# FLASH register map
Vendor: Texas Instruments
Peripheral module from a debugger description file (folder CC27xxx7).
Registers are 32-bit, read-only, reset 0x0 unless marked. A register's access mark holds for its fields unless they carry their own. Offsets are as the file gives them; lines under a group give offsets from that group; [hi:lo] are bit positions; {n}, {i} and the like mark numbered series; 'fields as' and 'values as' point back to an identical list; <NAME> marks a mode.

## FLASH — This is the MMR space for the flash wrapper. The flash wrapper is targeting multiple microcontroller platforms. The flash wrapper is a module that manages complex flash read, program and erase memory operations. The system is also given direct access to read flash memory contents directly for each instantiated flash bank through FBAP ports.
0x28 IMASK access per field — Interrupt Mask Register: The IMASK register holds the current interrupt mask settings. Masked interrupts are read in the MIS register. PSD compliant register.
  [0] DONE rw — Interrupt mask for DONE: 0: Interrupt is disabled in MIS register 1: Interrupt is enabled in MIS register
    1=ENABLED (Interrupt will request an interrupt service routine and corresponding bit in IPSTANDARD.MIS will be set); 0=DISABLED (Interrupt is masked out)
0x30 RIS — Raw Interrupt Status Register: The RIS register reflects all pending interrupts, regardless of masking. The RIS register allows the user to implement a poll scheme. A flag set in this register can be cleared by writing a 1 to the ICLR register bit even if the corresponding IMASK bit is not enabled. A flag can be set by software by writing a 1 to the ISET register. Reading the IIDX register will also clear the corresponding bit in RIS. PSD compliant register.
  [0] DONE — Flash wrapper operation completed. This interrupt bit is set by firmware or the corresponding bit in the ISET register. It is cleared by the corresponding bit in in the ICLR register or reading the IIDX register when this interrupt is the highest priority.
    1=SET (Interrupt occurred); 0=CLR (Interrupt did not occur)
0x38 MIS — Masked Interrupt Status Register: The MIS register is a bit-wise AND of the contents of the IMASK and RIS registers. This is kept mainly for ARM compatibility, and has limited use since the highest priority interrupt index is returned through the IIDX register. PSD compliant register.
  [0] DONE — Flash wrapper operation completed. This masked interrupt bit reflects the bitwise AND of the corresponding RIS and IMASK bits.
    1=SET (Masked interrupt occurred); 0=CLR (Masked interrupt did not occur)
0x40 ISET wo — Interrupt Set Register: The ISET register allows software to write a 1 to set corresponding interrupt. Safety: This meets a safety requirement to allow software diagnostics to trigger interrupts. PSD compliant register.
  [0] DONE — 0: No effect 1: Set the DONE interrupt in the RIS register
    1=SET (Set IPSTANDARD.RIS bit); 0=NO_EFFECT (Writing a 0 has no effect)
0x48 ICLR wo — Interrupt Clear Register. The ICLR register allows allows software to write a 1 to clear corresponding interrupt. PSD compliant register.
  [0] DONE — 0: No effect 1: Clear the DONE interrupt in the RIS register
    1=CLR (Clear IPSTANDARD.RIS bit); 0=NO_EFFECT (Writing a 0 has no effect)
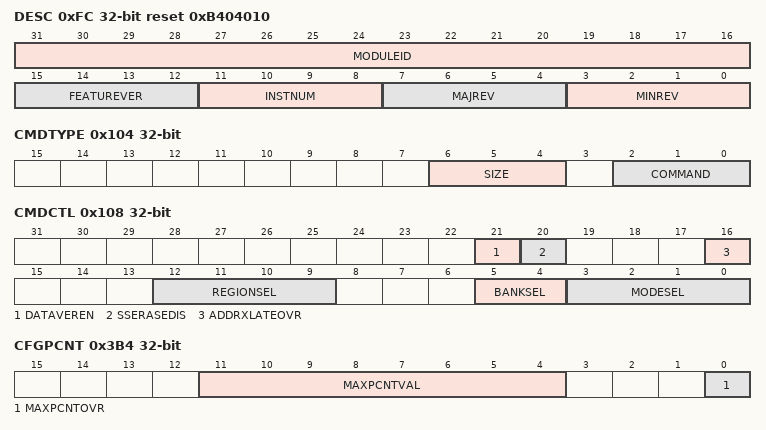
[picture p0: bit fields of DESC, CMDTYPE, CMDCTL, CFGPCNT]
0xFC DESC reset 0xB404010 — Hardware Version Description Register: This register identifies the flash wrapper hardware version and feature set used.
  [31:16] MODULEID
    0xFFFF=MAXIMUM (Highest possible value); 0=MINIMUM (Smallest value)
  [15:12] FEATUREVER — Feature set
    15=MAXIMUM (Maximum Value); 0=MINIMUM (Minimum Value)
  [11:8] INSTNUM — Instance number
    15=MAXIMUM (Highest possible value); 0=MINIMUM (Smallest value)
  [7:4] MAJREV — Major Revision
    values as INSTNUM
  [3:0] MINREV — Minor Revision
    values as INSTNUM
0x100 CMDEXEC access per field — Command Execute Register: Initiates execution of the command specified in the CMDTYPE register. This register is blocked for writes after being written to 1 and prior to STATCMD.DONE being set by the flash wrapper hardware. flash wrapper hardware clears this register after the processing of the command has completed.
  [0] VAL rw — Command Execute value Initiates execution of the command specified in the CMDTYPE register.
    1=EXECUTE (Command will execute or is executing in flash wrapper); 0=NOEXECUTE (Command will not execute or is not executing in flash wrapper)
0x104 CMDTYPE access per field — Command Type Register This register specifies the type of command to be executed by the flash wrapper hardware. This register is blocked for writes after CMDEXEC is written to a 1 and prior to STATCMD.DONE being set by the hardware to indicate that command execution has completed.
  [6:4] SIZE rw — Command size
    5=BANK (Operate on an entire flash bank); 4=SECTOR (Operate on a flash sector); 3=EIGHTWORD (Operate on 8 flash words); 2=FOURWORD (Operate on 4 flash words); 1=TWOWORD (Operate on 2 flash words); 0=ONEWORD (Operate on 1 flash word)
  [2:0] COMMAND rw — Command type
    6=BLANKVERIFY (Blank Verify - Check whether a flash word is in the erased state. This command may only be used with CMDTYPE.SIZE = ONEWORD); 5=CLEARSTATUS (Clear Status - Clear status bits in FW_SMSTAT only.); 4=MODECHANGE (Mode Change - Perform a mode change only, no other operation.); 2=ERASE; 1=PROGRAM; 0=NOOP (No Operation)
0x108 CMDCTL access per field — Command Control Register This register configures specific capabilities of the state machine for related to the execution of a command. This register is blocked for writes after CMDEXEC is written to a 1 and prior to STATCMD.DONE being set by the hardware to indicate that command execution has completed.
  [21] DATAVEREN rw — Enable invalid data verify. This checks for 0-$gt;1 transitions in the memory when a program operation is initiated. If such a transition is found, the program will fail with an error without executing the program.
    1=ENABLE; 0=DISABLE
  [20] SSERASEDIS rw — Disable Stair-Step Erase. If set, the default VHV trim voltage setting will be used for all erase pulses. By default, this bit is reset, meaning that the VHV voltage will be stepped during successive erase pulses. The step count, step voltage, begin and end voltages are all hard-wired.
    1=DISABLE; 0=ENABLE
  [16] ADDRXLATEOVR rw — Override hardware address translation of address in CMDADDR from a system address to a bank address and bank ID. Use data written to CMDADDR directly as the bank address. Use the value written to CMDCTL.BANKSEL directly as the bank ID. Use the value written to CMDCTL.REGIONSEL directly as the region ID.
    1=OVERRIDE; 0=NOOVERRIDE (Do not override)
  [12:9] REGIONSEL rw — Bank Region A specific region ID can be written to this field to indicate to which region an operation is to be applied if CMDCTL.ADDRXLATEOVR is set.
    8=ENGR (Engr Region); 4=TRIM (Trim Region); 2=NONMAIN (Non-Main Region); 1=MAIN (Main Region)
  [5:4] BANKSEL rw — Bank Select A specific Bank ID can be written to this field to indicate to which bank an operation is to be applied if CMDCTL.ADDRXLATEOVR is set.
  [3:0] MODESEL rw — Mode This field is only used for the Mode Change command type. Otherwise, bank and pump modes are set automaticlly through the NW hardware.
    15=ERASEBNK (Erase Bank); 14=PGMMW (Program Multiple Word); 12=ERASESECT (Erase Sector); 11=ERASEVER (Erase Verify Mode); 10=PGMSW (Program Single Word); 9=PGMVER (Program Verify Mode); 7=RDMARG1B (Read Margin 1B Mode); 6=RDMARG0B (Read Margin 0B Mode); 4=RDMARG1 (Read Margin 1 Mode); 2=RDMARG0 (Read Margin 0 Mode); 0=READ (Read Mode)
0x120 CMDADDR rw — Command Address Register: This register forms the target address of a command. The use cases are as follows: 1) For single-word program, this address indicates the flash bank word to be programmed. 2) For multi-word program, this address indicates the first flash bank address for the program. The address will be incremented for further words. 3) For sector erase, this address indicates the sector to be erased. 4) For bank erase, the address indicates the bank to be erased. Note the address written to this register will be submitted for translation to the flash wrapper address translation interface, and the translated address will be used to access the bank. However, if the CMDCTL.ADDRXLATEOVR bit is set, then the address written to this register will be used directly as the bank address. This register is blocked for writes after a 1 is written to the CMDEXEC register and prior to STATCMD.DONE being set by the flash wrapper hardware.
  [31:0] VAL — Address value
    0xFFFFFFFF=MAXIMUM (Maximum value of VAL); 0=MINIMUM (Minimum value of VAL)
0x124 CMDBYTEN access per field — Command Program Byte Enable Register: This register forms a per-byte enable for programming data. For data bytes to be programmed, a 1 must be written to the corresponding bit in this register. Normally, all bits are written to 1, allowing program of full flash words. However, leaving some bits 0 allows programming of 8-bit, 16-bit, 32-bit or 64-bit portions of a flash word. During verify, data bytes read from the flash will not be checked if the corresponding CMDBYTEN bit is 0. ECC data bytes are protected by the 1-2 MSB bits in this register, depending on the presence of ECC and the flash word data width. This register is blocked for writes after a 1 is written to the CMDEXEC register and prior to STATCMD.DONE being set by the flash wrapper hardware. This register is written to all 0 after the completion of all flash wrapper commands.
  [15:0] VAL rw — Command Byte Enable value. A 1-bit per flash word byte value is placed in this register.
0x130 CMDDATA0 rw reset 0xFFFFFFFF — Command Data Register 0 This register forms the data for a command. For DATAWIDTH == 128: This register represents bits 31:0 of flash word data register 0. For DATAWIDTH == 64: This register represents bits 31:0 of flash word data register 0. This register is blocked for writes after a 1 is written to the CMDEXEC register and prior to STATCMD.DONE being set by the flash wrapper hardware. This register is used to aggregate masking for bits that do not require additional program pulses during program operations, and will be written to all 1 after the completion of all flash wrapper commands. Use cases for the CMDDATA* registers are as follows: 1) Program - These registers contain the data to be programmed. 2) Erase - These registers are not used.
  [31:0] VAL — A 32-bit data value is placed in this field.
    values as CMDADDR.VAL
0x134 CMDDATA1 rw reset 0xFFFFFFFF — Command Data Register 1 This register forms the data for a command. For DATAWIDTH == 128: This register represents bits 63:32 of flash word data register 0. For DATAWIDTH == 64: This register represents bits 63:32 of flash word data register 0. This register is blocked for writes after a 1 is written to the CMDEXEC register and prior to CMDSTAT.DONE being set by the flash wrapper hardware. This register is used to aggregate masking for bits that do not require additional program pulses during program operations, and will be written to all 1 after the completion of all flash wrapper commands. Use cases for the CMDDATA* registers are as follows: 1) Program - These registers contain the data to be programmed. 2) Erase - These registers are not used.
  fields as CMDDATA0
0x138 CMDDATA2 rw reset 0xFFFFFFFF — Command Data Register 2 This register forms the data for a command. For DATAWIDTH == 128: This register represents bits 95:64 of flash word data register 0. For DATAWIDTH == 64: This register represents bits 31:0 of flash word data register 1. This register is blocked for writes after a 1 is written to the CMDEXEC register and prior to STATCMD.DONE being set by the flash wrapper hardware. This register is used to aggregate masking for bits that do not require additional program pulses during program operations, and will be written to all 1 after the completion of all flash wrapper commands. Use cases for the CMDDATA* registers are as follows: 1) Program - These registers contain the data to be programmed. 2) Erase - These registers are not used.
  fields as CMDDATA0
0x13C CMDDATA3 rw reset 0xFFFFFFFF — Command Data Register 3 This register forms the data for a command. For DATAWIDTH == 128: This register represents bits 127:96 of flash word data register 0. For DATAWIDTH == 64: This register represents bits 63:32 of flash word data register 1. This register is blocked for writes after a 1 is written to the CMDEXEC register and prior to STATCMD.DONE being set by the flash wrapper hardware. This register is used to aggregate masking for bits that do not require additional program pulses during program operations, and will be written to all 1 after the completion of all flash wrapper commands. Use cases for the CMDDATA* registers are as follows: 1) Program - These registers contain the data to be programmed. 2) Erase - These registers are not used.
  fields as CMDDATA0
0x1D0 CMDWEPROTA rw reset 0xFFFFFFFF — Command WriteErase Protect A Register This register allows the first 32 sectors of the main region to be protected from program or erase, with 1 bit protecting each sector. If the main region size is smaller than 32 sectors, then this register provides protection for the whole region. This register is blocked for writes after a 1 is written to the CMDEXEC register and prior to STATCMD.DONE being set by the flash wrapper hardware. In addition, this register is used to aggregate masking for sectors that do not require additional erase pulses during bank erase operations, and will be written to all 1 after the completion of all flash wrapper commands.
  [31:0] VAL — Each bit protects 1 sector. bit [0]: When 1, sector 0 of the flash memory will be protected from program and erase. bit [1]: When 1, sector 1 of the flash memory will be protected from program and erase. : : bit [31]: When 1, sector 31 of the flash memory will be protected from program and erase.
    values as CMDADDR.VAL
0x1D4 CMDWEPROTB rw reset 0xFFFFFFFF — Command WriteErase Protect B Register This register allows main region sectors to be protected from program and erase. Each bit corresponds to a group of 8 sectors. There are multiple cases for how these protect bits are applied: 1. Single-bank system, CMDWEPROTA register present: The first 32 sectors are protected via the CMDWEPROTA register. Thus, the protection given by the bits in CMDWEPROTB begin with sector 32. 2. Single-bank system, CMDWEPROTA register not present: The protection given by the bits in CMDWEPROTB begin with sector 0. 3. Multi-bank system, CMDWEPROTA register present - Bank 0: The first 32 sectors of bank 0 are protected via the CMDWEPROTA register. Thus, only bits 4 and above of CMDWEPROTB would be applicable to bank 0. The protection of bit 4 and above would begin at sector 32. Bits 3:0 of WEPROTB are ignored for bank 0. 4. Multi-bank system, CMDWEPROTA register present, Banks 1-N: For banks other than bank 0 in a multi-bank system, CMDWEPROTA has no effect, so the bits in CMDWEPROTB will protect these banks starting from sector 0. 5. Multi-bank system, CMDWEPROTA register not present: The bits in CMDWEPROTB will protect any of the banks starting from sector 0. This register is blocked for writes after a 1 is written to the CMDEXEC register and prior to STATCMD.DONE being set by the flash wrapper hardware. In addition, this register is used to aggregate masking for sectors that do not require additional erase pulses during bank erase operations, and will be written to all 1 after the completion of all flash wrapper commands.
  [31:0] VAL — Each bit protects a group of 8 sectors. When a bit is 1, the associated 8 sectors in the flash will be protected from program and erase. A maximum of 256 sectors can be protected with this register.
    values as CMDADDR.VAL
0x210 CMDWEPROTNM access per field reset 0x3 — Command WriteErase Protect Non-Main Register This register allows non-main region region sectors to be protected from program and erase. Each bit corresponds to 1 sector. This register is blocked for writes after a 1 is written to the CMDEXEC register and prior to STATCMD.DONE being set by the flash wrapper hardware. In addition, this register is used to aggregate masking for sectors that do not require additional erase pulses during bank erase operations, and will be written to all 1 after the completion of all flash wrapper commands.
  [1:0] VAL rw — Each bit protects 1 sector. bit [0]: When 1, sector 0 of the non-main region will be protected from program and erase. bit [1]: When 1, sector 1 of the non-main region will be protected from program and erase. : : bit [31]: When 1, sector 31 of the non-main will be protected from program and erase.
0x214 CMDWEPROTTR access per field reset 0x1 — Command WriteErase Protect Trim Register This register allows trim region sectors to be protected from program and erase. Each bit corresponds to 1 sector. This register is blocked for writes after a 1 is written to the CMDEXEC register and prior to STATCMD.DONE being set by the flash wrapper hardware. In addition, this register is used to aggregate masking for sectors that do not require additional erase pulses during bank erase operations, and will be written to all 1 after the completion of all flash wrapper commands.
  [0] VAL rw — Each bit protects 1 sector. bit [0]: When 1, sector 0 of the engr region will be protected from program and erase. bit [1]: When 1, sector 1 of the engr region will be protected from program and erase. : : bit [31]: When 1, sector 31 of the engr region will be protected from program and erase.
0x218 CMDWEPROTEN access per field reset 0x1 — Command WriteErase Protect Engr Register This register allows engr region sectors to be protected from program and erase. Each bit corresponds to 1 sector. This register is blocked for writes after a 1 is written to the CMDEXEC register and prior to STATCMD.DONE being set by the flash wrapper hardware. In addition, this register is used to aggregate masking for sectors that do not require additional erase pulses during bank erase operations, and will be written to all 1 after the completion of all flash wrapper commands.
  fields as CMDWEPROTTR
0x3B0 CFGCMD access per field reset 0x2 — Command Configuration Register This register configures specific capabilities of the state machine for related to the execution of a command. This register is blocked for writes after CMDEXEC is written to a 1 and prior to STATCMD.DONE being set by the hardware to indicate that command execution has completed.
  [3:0] WAITSTATE rw — Wait State setting for verify reads
    15=MAXIMUM (Maximum value); 0=MINIMUM (Minimum value)
0x3B4 CFGPCNT access per field — Pulse Counter Configuration Register This register allows further configuration of maximum pulse counts for program and erase operations. This register is blocked for writes after a 1 is written to the CMDEXEC register and prior to STATCMD.DONE being set by the flash wrapper hardware.
  [11:4] MAXPCNTVAL rw — Override maximum pulse counter with this value. If MAXPCNTOVR = 0, then this field is ignored. If MAXPCNTOVR = 1 and MAXERSPCNTOVR = 0, then this value will be used to override the max pulse count for both program and erase. Full max value will be {4'h0, MAXPCNTVAL} . If MAXPCNTOVR = 1 and MAXERSPCNTOVR = 1, then this value will be used to override the max pulse count for program only. Full max value will be {4'h0, MAXPCNTVAL}.
    255=MAXIMUM (Maximum value); 0=MINIMUM (Minimum value)
  [0] MAXPCNTOVR rw — Override hard-wired maximum pulse count. If MAXERSPCNTOVR is not set, then setting this value alone will override the max pulse count for both program and erase. If MAXERSPCNTOVR is set, then this bit will only control the max pulse count setting for program. By default, this bit is 0, and a hard-wired max pulse count is used.
    1=OVERRIDE (Use value from MAXPCNTVAL field as maximum puse count); 0=DEFAULT (Use hard-wired (default) value for maximum pulse count)
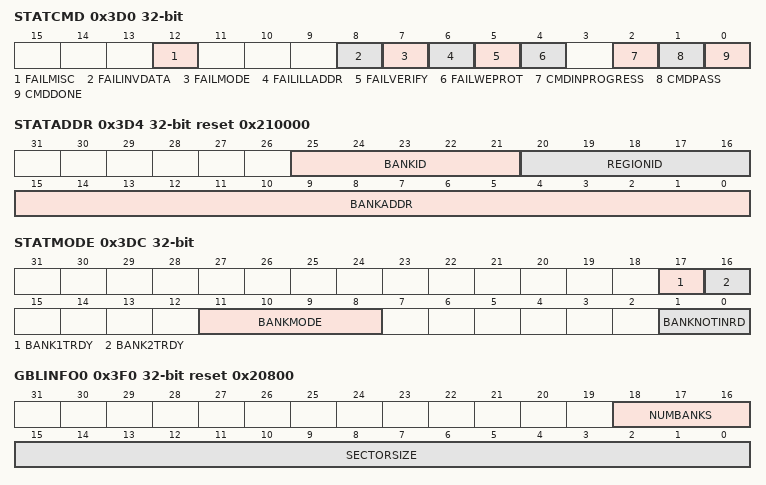
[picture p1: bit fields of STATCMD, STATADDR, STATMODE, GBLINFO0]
0x3D0 STATCMD — Command Status Register This register contains status regarding completion and errors of command execution.
  [12] FAILMISC — Command failed due to error other than write/erase protect violation or verify error. This is an extra bit in case a new failure mechanism is added which requires a status bit.
    1=STATFAIL (Fail); 0=STATNOFAIL (No Fail)
  [8] FAILINVDATA — Program command failed because an attempt was made to program a stored 0 value to a 1.
    1=STATFAIL (Fail); 0=STATNOFAIL (No Fail)
  [7] FAILMODE — Command failed because a bank has been set to a mode other than READ. Program and Erase commands cannot be initiated unless all banks are in READ mode.
    1=STATFAIL (Fail); 0=STATNOFAIL (No Fail)
  [6] FAILILLADDR — Command failed due to the use of an illegal address
    1=STATFAIL (Fail); 0=STATNOFAIL (No Fail)
  [5] FAILVERIFY — Command failed due to verify error
    1=STATFAIL (Fail); 0=STATNOFAIL (No Fail)
  [4] FAILWEPROT — Command failed due to Write/Erase Protect Sector Violation
    1=STATFAIL (Fail); 0=STATNOFAIL (No Fail)
  [2] CMDINPROGRESS — Command In Progress
    1=STATINPROGRESS (In Progress); 0=STATCOMPLETE (Complete)
  [1] CMDPASS — Command Pass - valid when CMD_DONE field is 1
    1=STATPASS (Pass); 0=STATFAIL (Fail)
  [0] CMDDONE — Command Done
    1=STATDONE (Done); 0=STATNOTDONE (Not Done)
0x3D4 STATADDR reset 0x210000 — Current Address Counter Value Read only register giving read access to the state machine current address. A bank id, region id and address are stored in this register and are incremented as necessary during execution of a command.
  [25:21] BANKID — Current Bank ID A bank indicator is stored in this register which represents the current bank on which the state machine is operating. There is 1 bit per bank.
    16=BANK4; 8=BANK3; 4=BANK2; 2=BANK1; 1=BANK0
  [20:16] REGIONID — Current Region ID A region indicator is stored in this register which represents the current flash region on which the state machine is operating.
    values as CMDCTL.REGIONSEL
  [15:0] BANKADDR — Current Bank Address A bank offset address is stored in this register.
    0xFFFF=MAXIMUM (Maximum value); 0=MINIMUM (Minimum value)
0x3D8 STATPCNT — Current Pulse Count Register: Read only register giving read access to the state machine current pulse count value for program/erase operations.
  [11:0] PULSECNT — Current Pulse Counter Value
    0xFFF=MAXIMUM (Maximum value); 0=MINIMUM (Minimum value)
0x3DC STATMODE — Mode Status Register Indicates one or more banks which not in READ mode, and it indicates the mode which the bank(s) are in.
  [17] BANK1TRDY — Bank 1T Ready. Bank(s) are ready for 1T access. This is accomplished when the bank and pump have been trimmed.
    1=TRUE (Ready); 0=FALSE (Not ready)
  [16] BANK2TRDY — Bank 2T Ready. Bank(s) are ready for 2T access. This is accomplished when the pump has fully driven power rails to the bank(s).
    1=TRUE (Ready); 0=FALSE (Not ready)
  [11:8] BANKMODE — Indicates mode of bank(s) that are not in READ mode
    values as CMDCTL.MODESEL
  [1:0] BANKNOTINRD — Bank not in read mode. Indicates which banks are not in READ mode. There is 1 bit per bank.
0x3F0 GBLINFO0 reset 0x20800 — Global Info 0 Register Read only register detailing information about sector size and number of banks present.
  [18:16] NUMBANKS — Number of banks instantiated Minimum: 1 Maximum: 5
    5=MAXIMUM (Maximum value); 1=MINIMUM (Minimum value)
  [15:0] SECTORSIZE — Sector size in bytes
    0x800=TWOKB (Sector size is TWOKB); 0x400=ONEKB (Sector size is ONEKB)
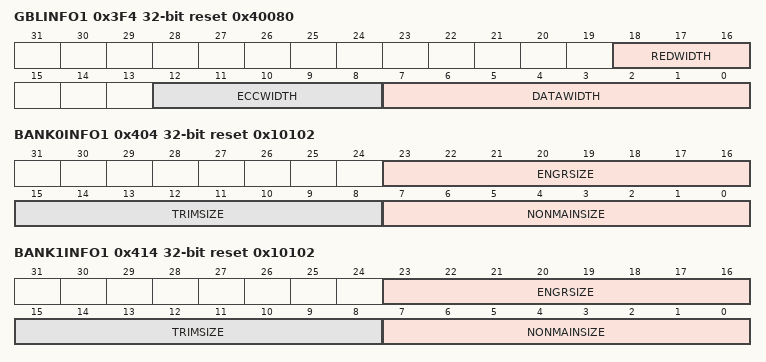
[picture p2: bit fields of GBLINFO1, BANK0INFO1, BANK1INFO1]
0x3F4 GBLINFO1 reset 0x40080 — Global Info 1 Register Read only register detailing information about data, ecc and redundant data widths in bits.
  [18:16] REDWIDTH — Redundant data width in bits
    4=W4BIT (Redundant data width is 4 bits); 2=W2BIT (Redundant data width is 2 bits); 0=W0BIT (Redundant data width is 0. Redundancy/Repair not present.)
  [12:8] ECCWIDTH — ECC data width in bits
    16=W16BIT (ECC data width is 16 bits); 8=W8BIT (ECC data width is 8 bits); 0=W0BIT (ECC data width is 0. ECC not used.)
  [7:0] DATAWIDTH — Data width in bits
    128=W128BIT (Data width is 128 bits); 64=W64BIT (Data width is 64 bits)
0x3F8 GBLINFO2 reset 0x1 — Global Info 2 Register Read only register detailing information about the number of data registers present.
  [3:0] DATAREGISTERS — Number of data registers present.
    8=MAXIMUM (Maximum value of DATAREGISTERS); 1=MINIMUM (Minimum value of DATAREGISTERS)
0x400 BANK0INFO0 reset 0x100 — Bank Info 0 Register for bank 0. Read only register detailing information about Main region size in the bank.
  [11:0] MAINSIZE — Main region size in sectors Minimum: 0x8 (8) Maximum: 0x200 (512)
    0x200=MAXSECTORS (Maximum value of MAINSIZE); 8=MINSECTORS (Minimum value of MAINSIZE)
0x404 BANK0INFO1 reset 0x10102 — Bank Info1 Register for bank 0. Read only register detailing information about Non-Main, Trim, and Engr region sizes in the bank.
  [23:16] ENGRSIZE — Engr region size in sectors Minimum: 0x0 (0) Maximum: 0x10 (16)
    32=MAXSECTORS (Maximum value of ENGRSIZE); 0=MINSECTORS (Minimum value of ENGRSIZE)
  [15:8] TRIMSIZE — Trim region size in sectors Minimum: 0x0 (0) Maximum: 0x10 (16)
    32=MAXSECTORS (Maximum value of TRIMSIZE); 0=MINSECTORS (Minimum value of TRIMSIZE)
  [7:0] NONMAINSIZE — Non-main region size in sectors Minimum: 0x0 (0) Maximum: 0x10 (16)
    32=MAXSECTORS (Maximum value of NONMAINSIZE); 0=MINSECTORS (Minimum value of NONMAINSIZE)
0x410 BANK1INFO0 reset 0x100 — Bank Info 0 Register for bank 1. Read only register detailing information about Main region size in the bank.
  fields as BANK0INFO0
0x414 BANK1INFO1 reset 0x10102 — Bank Info1 Register for bank 1. Read only register detailing information about Non-Main, Trim, and Engr region sizes in the bank.
  [23:16] ENGRSIZE — Engr region size in sectors Minimum: 0x0 (0) Maximum: 0x10 (16)
    values as BANK0INFO1.ENGRSIZE
  [15:8] TRIMSIZE — Trim region size in sectors
    values as BANK0INFO1.TRIMSIZE
  [7:0] NONMAINSIZE — Non-main region size in sectors
    values as BANK0INFO1.NONMAINSIZE
